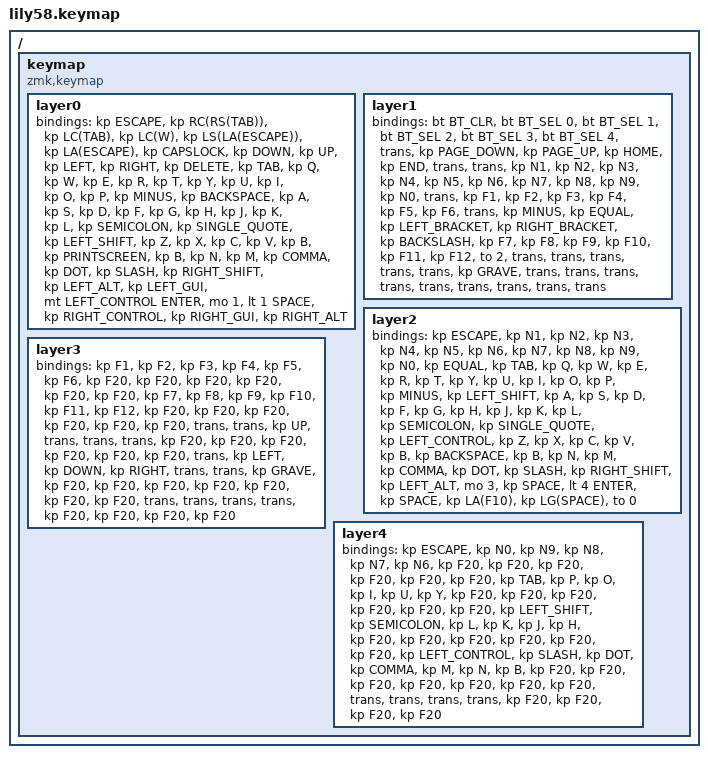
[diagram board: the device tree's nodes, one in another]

  /*
  * Copyright (c) 2020 The ZMK Contributors
  *
  * SPDX-License-Identifier: MIT
  */

  #include <behaviors.dtsi>
  #include <dt-bindings/zmk/keys.h>
  #include <dt-bindings/zmk/bt.h>
  #include <dt-bindings/zmk/ext_power.h>

  / {
    keymap {
      compatible = "zmk,keymap";
  layer0 {
          bindings = <
          &kp ESCAPE &kp RC(RS(TAB)) &kp LC(TAB) &kp LC(W) &kp LS(LA(ESCAPE)) &kp LA(ESCAPE) &kp CAPSLOCK &kp DOWN &kp UP &kp LEFT &kp RIGHT &kp DELETE &kp TAB &kp Q &kp W &kp E &kp R &kp T &kp Y &kp U &kp I &kp O &kp P &kp MINUS &kp BACKSPACE &kp A &kp S &kp D &kp F &kp G &kp H &kp J &kp K &kp L &kp SEMICOLON &kp SINGLE_QUOTE &kp LEFT_SHIFT &kp Z &kp X &kp C &kp V &kp B &kp PRINTSCREEN &kp B &kp N &kp M &kp COMMA &kp DOT &kp SLASH &kp RIGHT_SHIFT &kp LEFT_ALT &kp LEFT_GUI &mt LEFT_CONTROL ENTER &mo 1 &lt 1 SPACE &kp RIGHT_CONTROL &kp RIGHT_GUI &kp RIGHT_ALT
          >;
        };layer1 {
          bindings = <
          &bt BT_CLR &bt BT_SEL 0 &bt BT_SEL 1 &bt BT_SEL 2 &bt BT_SEL 3 &bt BT_SEL 4 &trans &kp PAGE_DOWN &kp PAGE_UP &kp HOME &kp END &trans &trans &kp N1 &kp N2 &kp N3 &kp N4 &kp N5 &kp N6 &kp N7 &kp N8 &kp N9 &kp N0 &trans &kp F1 &kp F2 &kp F3 &kp F4 &kp F5 &kp F6 &trans &kp MINUS &kp EQUAL &kp LEFT_BRACKET &kp RIGHT_BRACKET &kp BACKSLASH &kp F7 &kp F8 &kp F9 &kp F10 &kp F11 &kp F12 &to 2 &trans &trans &trans &trans &trans &kp GRAVE &trans &trans &trans &trans &trans &trans &trans &trans &trans
          >;
        };layer2 {
          bindings = <
          &kp ESCAPE &kp N1 &kp N2 &kp N3 &kp N4 &kp N5 &kp N6 &kp N7 &kp N8 &kp N9 &kp N0 &kp EQUAL &kp TAB &kp Q &kp W &kp E &kp R &kp T &kp Y &kp U &kp I &kp O &kp P &kp MINUS &kp LEFT_SHIFT &kp A &kp S &kp D &kp F &kp G &kp H &kp J &kp K &kp L &kp SEMICOLON &kp SINGLE_QUOTE &kp LEFT_CONTROL &kp Z &kp X &kp C &kp V &kp B &kp BACKSPACE &kp B &kp N &kp M &kp COMMA &kp DOT &kp SLASH &kp RIGHT_SHIFT &kp LEFT_ALT &mo 3 &kp SPACE &lt 4 ENTER &kp SPACE &kp LA(F10) &kp LG(SPACE) &to 0
          >;
        };layer3 {
          bindings = <
          &kp F1 &kp F2 &kp F3 &kp F4 &kp F5 &kp F6 &kp F20 &kp F20 &kp F20 &kp F20 &kp F20 &kp F20 &kp F7 &kp F8 &kp F9 &kp F10 &kp F11 &kp F12 &kp F20 &kp F20 &kp F20 &kp F20 &kp F20 &kp F20 &trans &trans &kp UP &trans &trans &trans &kp F20 &kp F20 &kp F20 &kp F20 &kp F20 &kp F20 &trans &kp LEFT &kp DOWN &kp RIGHT &trans &trans &kp GRAVE &kp F20 &kp F20 &kp F20 &kp F20 &kp F20 &kp F20 &kp F20 &trans &trans &trans &trans &kp F20 &kp F20 &kp F20 &kp F20
          >;
        };layer4 {
          bindings = <
          &kp ESCAPE &kp N0 &kp N9 &kp N8 &kp N7 &kp N6 &kp F20 &kp F20 &kp F20 &kp F20 &kp F20 &kp F20 &kp TAB &kp P &kp O &kp I &kp U &kp Y &kp F20 &kp F20 &kp F20 &kp F20 &kp F20 &kp F20 &kp LEFT_SHIFT &kp SEMICOLON &kp L &kp K &kp J &kp H &kp F20 &kp F20 &kp F20 &kp F20 &kp F20 &kp F20 &kp LEFT_CONTROL &kp SLASH &kp DOT &kp COMMA &kp M &kp N &kp B &kp F20 &kp F20 &kp F20 &kp F20 &kp F20 &kp F20 &kp F20 &trans &trans &trans &trans &kp F20 &kp F20 &kp F20 &kp F20
          >;
        };
    };
  };
  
